# CC430F5123 register map
Registers are 16-bit, read-write, reset 0x0 unless marked. A register's access mark holds for its fields unless they carry their own. Offsets are from the block's base; [hi:lo] are bit positions.

## CC1101_Radio_Interface
Base 0x00000000
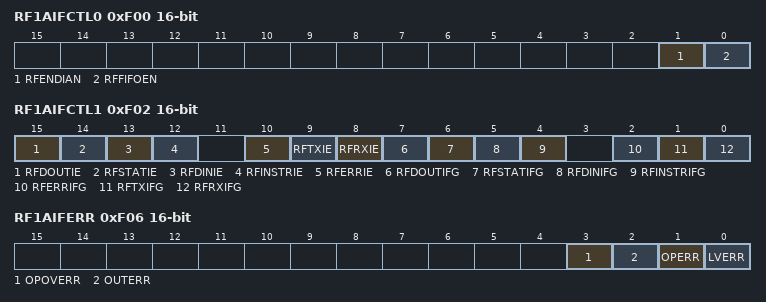
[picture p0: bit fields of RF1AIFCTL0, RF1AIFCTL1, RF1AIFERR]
0xF00 RF1AIFCTL0 — Radio interface control register 0
  [1] RFENDIAN — CC1101 Disable endianness conversion
  [0] RFFIFOEN — CC1101 Direct FIFO access enable
0xF02 RF1AIFCTL1 — Radio interface control register 1
  [15] RFDOUTIE — Radio interface data out interrupt enable
  [14] RFSTATIE — Radio interface status interrupt enable
  [13] RFDINIE — Radio interface data in interrupt enable
  [12] RFINSTRIE — Radio interface instruction interrupt enable
  [10] RFERRIE — Radio interface error interrupt enable
  [9] RFTXIE — Radio interface direct FIFO access transmit interrupt enable
  [8] RFRXIE — Radio interface direct FIFO access receive interrupt enable
  [7] RFDOUTIFG — Radio interface data out interrupt flag
  [6] RFSTATIFG — Radio interface status interrupt flag
  [5] RFDINIFG — Radio interface data in interrupt flag
  [4] RFINSTRIFG — Radio interface instruction interrupt flag
  [2] RFERRIFG — Radio interface error interrupt flag
  [1] RFTXIFG — Radio interface direct FIFO access transmit interrupt flag
  [0] RFRXIFG — Radio interface direct FIFO access receive interrupt flag
0xF04 RF1AIFCTL2 — (Radio interface control register 2)
0xF06 RF1AIFERR — Radio interface error flag register
  [3] OPOVERR — Operand Overwrite Error Flag
  [2] OUTERR — Output data not available Error Flag
  [1] OPERR — Operand Error Flag
  [0] LVERR — Low Core Voltage Error Flag
0xF0C RF1AIFERRV — Radio interface error vector word register
0xF0E RF1AIFIV — Radio interface interrupt vector word register
0xF10 RF1AINSTRW — Radio instruction word register
0xF12 RF1AINSTR1W — Radio instruction 1-byte register with autoread
0xF14 RF1AINSTR2W — Radio instruction 2-byte register with autoread
0xF16 RF1ADINW — Radio word data in register
0xF20 RF1ASTAT0W — Radio status word register without auto-read
0xF22 RF1ASTAT1W — Radio status word register with 1-byte auto-read
0xF24 RF1ASTAT2W — Radio status word register with 2-byte auto-read
0xF28 RF1ADOUT0W — Radio core word data out register without auto-read
0xF2A RF1ADOUT1W — Radio core word data out register with 1-byte auto-read
0xF2C RF1ADOUT2W — Radio core word data out register with 2-byte auto-read
0xF30 RF1AIN — Radio core signal input register
0xF32 RF1AIFG — Radio core interrupt flag register
0xF34 RF1AIES — Radio core interrupt edge select register
0xF36 RF1AIE — Radio core interrupt enable register
0xF38 RF1AIV — Radio core interrupt vector word register
0xF3C RF1ARXFIFO — Direct receive FIFO access register
0xF3E RF1ATXFIFO — Direct transmit FIFO access register

## CRC16
Base 0x00000000
0x150 CRCDI — CRC Data In Register
0x152 CRCDIRB — CRC data in reverse byte Register
0x154 CRCINIRES — CRC Initialisation Register and Result Register
0x156 CRCRESR — CRC reverse result Register

## Flash
Base 0x00000000
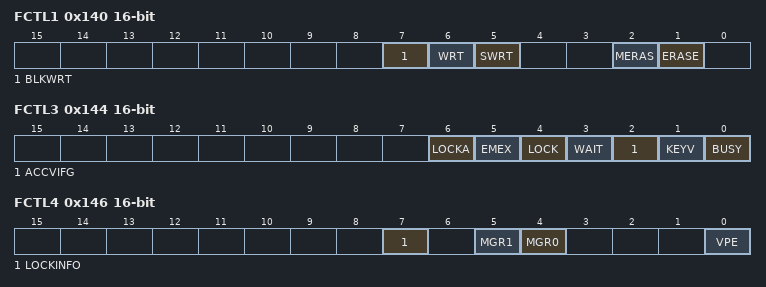
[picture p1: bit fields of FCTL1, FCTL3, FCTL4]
0x140 FCTL1 — FLASH Control 1
  [7] BLKWRT — Enable bit for Flash segment write
  [6] WRT — Enable bit for Flash write
  [5] SWRT — Smart Write enable
  [2] MERAS — Enable bit for Flash mass erase
  [1] ERASE — Enable bit for Flash segment erase
0x144 FCTL3 — FLASH Control 3
  [6] LOCKA — Segment A Lock bit: read = 1 - Segment is locked (read only)
  [5] EMEX — Flash Emergency Exit
  [4] LOCK — Lock bit: 1 - Flash is locked (read only)
  [3] WAIT — Wait flag for segment write
  [2] ACCVIFG — Flash Access violation flag
  [1] KEYV — Flash Key violation flag
  [0] BUSY — Flash busy: 1
0x146 FCTL4 — FLASH Control 4
  [7] LOCKINFO — Lock INFO Memory bit: read = 1 - Segment is locked (read only)
  [5] MGR1 — Marginal read 1 mode.
  [4] MGR0 — Marginal read 0 mode.
  [0] VPE — Voltage Changed during Program Error Flag

## MPY_16_Multiplier_16_Bit_Mode
Base 0x00000000
0x4C0 MPY — Multiply Unsigned/Operand 1
0x4C2 MPYS — Multiply Signed/Operand 1
0x4C4 MAC — Multiply Unsigned and Accumulate/Operand 1
0x4C6 MACS — Multiply Signed and Accumulate/Operand 1
0x4C8 OP2 — Operand 2
0x4CA RESLO — Result Low Word
0x4CC RESHI — Result High Word
0x4CE SUMEXT — Sum Extend
0x4EC MPY32CTL0 — MPY32 Control Register 0
  [9] MPYDLY32 — Delayed write mode
  [8] MPYDLYWRTEN — Delayed write enable
  [7] OP2_32 — Bit-width of operand 2 0:16Bit / 1:32Bit
  [6] OP1_32 — Bit-width of operand 1 0:16Bit / 1:32Bit
  [6:5] MPYM — Multiplier mode Bit:0
    0=Multiplier mode: MPY; 1=Multiplier mode: MPYS; 2=Multiplier mode: MAC; 3=Multiplier mode: MACS
  [3] MPYSAT — Saturation mode
  [2] MPYFRAC — Fractional mode
  [0] MPYC — Carry of the multiplier
